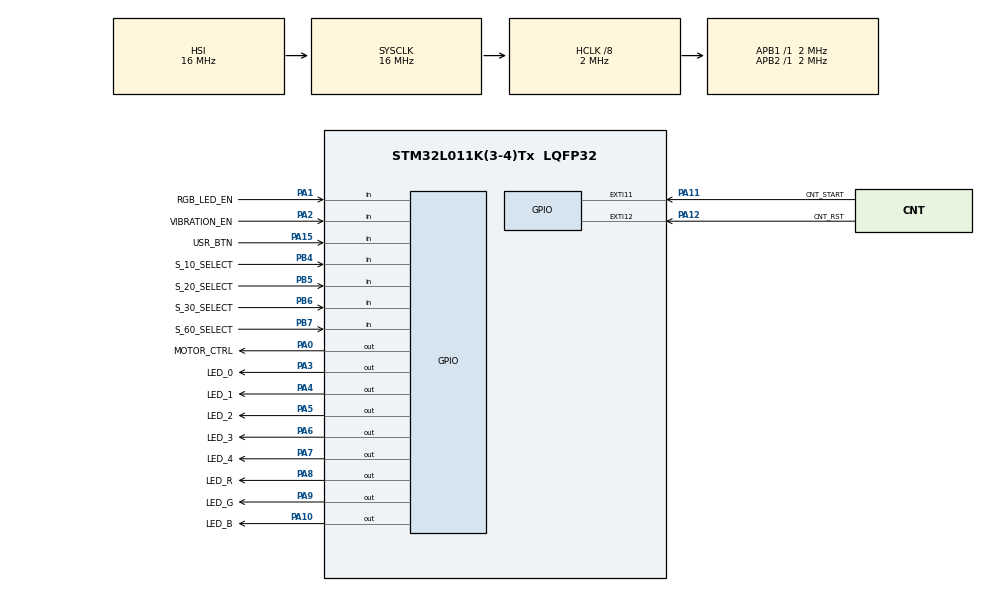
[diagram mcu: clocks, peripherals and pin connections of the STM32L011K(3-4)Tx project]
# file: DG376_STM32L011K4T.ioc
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Mcu.Family=STM32L0
Mcu.Name=STM32L011K(3-4)Tx
Mcu.Package=LQFP32
PA0-CK_IN.GPIO_Label=MOTOR_CTRL
PA0-CK_IN.Signal=GPIO_Output
PA1.GPIO_Label=RGB_LED_EN
PA1.GPIO_PuPd=GPIO_PULLDOWN
PA1.Signal=GPIO_Input
PA10.GPIO_Label=LED_B
PA10.Signal=GPIO_Output
PA11.GPIO_Label=CNT_START
PA11.GPIO_ModeDefaultEXTI=GPIO_MODE_IT_FALLING
PA11.GPIO_PuPd=GPIO_PULLUP
PA11.Signal=GPXTI11
PA12.GPIO_Label=CNT_RST
PA12.GPIO_PuPd=GPIO_PULLDOWN
PA12.Signal=GPXTI12
PA13.Mode=Serial_Wire
PA13.Signal=SYS_SWDIO
PA14.Mode=Serial_Wire
PA14.Signal=SYS_SWCLK
PA15.GPIO_Label=USR_BTN
PA15.GPIO_PuPd=GPIO_PULLUP
PA15.Signal=GPIO_Input
PA2.GPIO_Label=VIBRATION_EN
PA2.GPIO_PuPd=GPIO_PULLDOWN
PA2.Signal=GPIO_Input
PA3.GPIO_Label=LED_0
PA3.Signal=GPIO_Output
PA4.GPIO_Label=LED_1
PA4.Signal=GPIO_Output
PA5.GPIO_Label=LED_2
PA5.Signal=GPIO_Output
PA6.GPIO_Label=LED_3
PA6.Signal=GPIO_Output
PA7.GPIO_Label=LED_4
PA7.Signal=GPIO_Output
PA8.GPIO_Label=LED_R
PA8.Signal=GPIO_Output
PA9.GPIO_Label=LED_G
PA9.Signal=GPIO_Output
PB4.GPIO_Label=S_10_SELECT
PB4.GPIO_PuPd=GPIO_PULLDOWN
PB4.Signal=GPIO_Input
PB5.GPIO_Label=S_20_SELECT
PB5.GPIO_PuPd=GPIO_PULLDOWN
PB5.Signal=GPIO_Input
PB6.GPIO_Label=S_30_SELECT
PB6.GPIO_PuPd=GPIO_PULLDOWN
PB6.Signal=GPIO_Input
PB7.GPIO_Label=S_60_SELECT
PB7.GPIO_PuPd=GPIO_PULLDOWN
PB7.Signal=GPIO_Input
ProjectManager.HeapSize=0x200
ProjectManager.StackSize=0x400
ProjectManager.TargetToolchain=SW4STM32
RCC.ADCFreq_Value=16000000
RCC.AHBCLKDivider=RCC_SYSCLK_DIV8
RCC.AHBFreq_Value=2000000
RCC.APB1Freq_Value=2000000
RCC.APB1TimFreq_Value=2000000
RCC.APB2Freq_Value=2000000
RCC.APB2TimFreq_Value=2000000
RCC.HCLKFreq_Value=2000000
RCC.HSE_VALUE=8000000
RCC.HSI16_VALUE=16000000
RCC.HSI_VALUE=16000000
RCC.MSIClockRange=RCC_MSIRANGE_6
RCC.MSI_VALUE=4194000
RCC.SYSCLKFreq_VALUE=16000000
RCC.SYSCLKSource=RCC_SYSCLKSOURCE_HSI
RCC.VCOOutputFreq_Value=48000000
RCC.VDD_VALUE=3
VP_RTC_VS_RTC_Activate.Mode=RTC_Enabled
board=custom

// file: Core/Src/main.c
/* USER CODE BEGIN Header */
/**
 ******************************************************************************
 * @file           : main.c
 * @brief          : Main program body
 ******************************************************************************
 * @attention
 *
 * <h2><center>&copy; Copyright (c) 2020 STMicroelectronics.
 * All rights reserved.</center></h2>
 *
 * This software component is licensed by ST under BSD 3-Clause license,
 * the "License"; You may not use this file except in compliance with the
 * License. You may obtain a copy of the License at:
 *                        opensource.org/licenses/BSD-3-Clause
 *
 ******************************************************************************
 */
/* USER CODE END Header */

#include "main.h"

/* USER CODE BEGIN Includes */
#include "dg376_main.h"
/* USER CODE END Includes */

RTC_HandleTypeDef hrtc;

void SystemClock_Config(void);
static void MX_GPIO_Init(void);
static void MX_RTC_Init(void);

int main(void) {

  /* MCU Configuration--------------------------------------------------------*/

  /* Reset of all peripherals, Initializes the Flash interface and the Systick.
   */
  HAL_Init();

  /* Configure the system clock */
  SystemClock_Config();

  /* Initialize all configured peripherals */
  MX_GPIO_Init();
  MX_RTC_Init();

  /* Infinite loop */
  /* USER CODE BEGIN WHILE */
  while (1) {
    dg376_while_loop();
    /* USER CODE END WHILE */
  }
}

void SystemClock_Config(void) {
  RCC_OscInitTypeDef RCC_OscInitStruct = {0};
  RCC_ClkInitTypeDef RCC_ClkInitStruct = {0};
  RCC_PeriphCLKInitTypeDef PeriphClkInit = {0};

  /** Configure the main internal regulator output voltage
   */
  __HAL_PWR_VOLTAGESCALING_CONFIG(PWR_REGULATOR_VOLTAGE_SCALE1);
  /** Initializes the CPU, AHB and APB busses clocks
   */
  RCC_OscInitStruct.OscillatorType =
      RCC_OSCILLATORTYPE_HSI | RCC_OSCILLATORTYPE_LSI;
  RCC_OscInitStruct.HSIState = RCC_HSI_ON;
  RCC_OscInitStruct.HSICalibrationValue = RCC_HSICALIBRATION_DEFAULT;
  RCC_OscInitStruct.LSIState = RCC_LSI_ON;
  RCC_OscInitStruct.PLL.PLLState = RCC_PLL_NONE;
  if (HAL_RCC_OscConfig(&RCC_OscInitStruct) != HAL_OK) {
    Error_Handler();
  }
  /** Initializes the CPU, AHB and APB busses clocks
   */
  RCC_ClkInitStruct.ClockType = RCC_CLOCKTYPE_HCLK | RCC_CLOCKTYPE_SYSCLK |
                                RCC_CLOCKTYPE_PCLK1 | RCC_CLOCKTYPE_PCLK2;
  RCC_ClkInitStruct.SYSCLKSource = RCC_SYSCLKSOURCE_HSI;
  RCC_ClkInitStruct.AHBCLKDivider = RCC_SYSCLK_DIV8;
  RCC_ClkInitStruct.APB1CLKDivider = RCC_HCLK_DIV1;
  RCC_ClkInitStruct.APB2CLKDivider = RCC_HCLK_DIV1;

  if (HAL_RCC_ClockConfig(&RCC_ClkInitStruct, FLASH_LATENCY_0) != HAL_OK) {
    Error_Handler();
  }
  PeriphClkInit.PeriphClockSelection = RCC_PERIPHCLK_RTC;
  PeriphClkInit.RTCClockSelection = RCC_RTCCLKSOURCE_LSI;
  if (HAL_RCCEx_PeriphCLKConfig(&PeriphClkInit) != HAL_OK) {
    Error_Handler();
  }
}

static void MX_RTC_Init(void) {

  /** Initialize RTC Only
   */
  hrtc.Instance = RTC;
  hrtc.Init.HourFormat = RTC_HOURFORMAT_24;
  hrtc.Init.AsynchPrediv = 127;
  hrtc.Init.SynchPrediv = 255;
  hrtc.Init.OutPut = RTC_OUTPUT_DISABLE;
  hrtc.Init.OutPutRemap = RTC_OUTPUT_REMAP_NONE;
  hrtc.Init.OutPutPolarity = RTC_OUTPUT_POLARITY_HIGH;
  hrtc.Init.OutPutType = RTC_OUTPUT_TYPE_OPENDRAIN;
  if (HAL_RTC_Init(&hrtc) != HAL_OK) {
    Error_Handler();
  }
}

static void MX_GPIO_Init(void) {
  GPIO_InitTypeDef GPIO_InitStruct = {0};

  /* GPIO Ports Clock Enable */
  __HAL_RCC_GPIOA_CLK_ENABLE();
  __HAL_RCC_GPIOB_CLK_ENABLE();

  /*Configure GPIO pin Output Level */
  HAL_GPIO_WritePin(GPIOA,
                    MOTOR_CTRL_Pin | LED_0_Pin | LED_1_Pin | LED_2_Pin |
                        LED_3_Pin | LED_4_Pin | LED_R_Pin | LED_G_Pin |
                        LED_B_Pin,
                    GPIO_PIN_RESET);

  /*Configure GPIO pins : MOTOR_CTRL_Pin LED_0_Pin LED_1_Pin LED_2_Pin
                           LED_3_Pin LED_4_Pin LED_R_Pin LED_G_Pin
                           LED_B_Pin */
  GPIO_InitStruct.Pin = MOTOR_CTRL_Pin | LED_0_Pin | LED_1_Pin | LED_2_Pin |
                        LED_3_Pin | LED_4_Pin | LED_R_Pin | LED_G_Pin |
                        LED_B_Pin;
  GPIO_InitStruct.Mode = GPIO_MODE_OUTPUT_PP;
  GPIO_InitStruct.Pull = GPIO_NOPULL;
  GPIO_InitStruct.Speed = GPIO_SPEED_FREQ_LOW;
  HAL_GPIO_Init(GPIOA, &GPIO_InitStruct);

  /*Configure GPIO pins : RGB_LED_EN_Pin VIBRATION_EN_Pin */
  GPIO_InitStruct.Pin = RGB_LED_EN_Pin | VIBRATION_EN_Pin;
  GPIO_InitStruct.Mode = GPIO_MODE_INPUT;
  GPIO_InitStruct.Pull = GPIO_PULLDOWN;
  HAL_GPIO_Init(GPIOA, &GPIO_InitStruct);

  /*Configure GPIO pin : CNT_START_Pin */
  GPIO_InitStruct.Pin = CNT_START_Pin;
  GPIO_InitStruct.Mode = GPIO_MODE_IT_FALLING;
  GPIO_InitStruct.Pull = GPIO_PULLUP;
  HAL_GPIO_Init(CNT_START_GPIO_Port, &GPIO_InitStruct);

  /*Configure GPIO pin : CNT_RST_Pin */
  GPIO_InitStruct.Pin = CNT_RST_Pin;
  GPIO_InitStruct.Mode = GPIO_MODE_IT_RISING;
  GPIO_InitStruct.Pull = GPIO_PULLDOWN;
  HAL_GPIO_Init(CNT_RST_GPIO_Port, &GPIO_InitStruct);

  /*Configure GPIO pin : USR_BTN_Pin */
  GPIO_InitStruct.Pin = USR_BTN_Pin;
  GPIO_InitStruct.Mode = GPIO_MODE_INPUT;
  GPIO_InitStruct.Pull = GPIO_PULLUP;
  HAL_GPIO_Init(USR_BTN_GPIO_Port, &GPIO_InitStruct);

  /*Configure GPIO pins : S_10_SELECT_Pin S_20_SELECT_Pin S_30_SELECT_Pin
   * S_60_SELECT_Pin */
  GPIO_InitStruct.Pin =
      S_10_SELECT_Pin | S_20_SELECT_Pin | S_30_SELECT_Pin | S_60_SELECT_Pin;
  GPIO_InitStruct.Mode = GPIO_MODE_INPUT;
  GPIO_InitStruct.Pull = GPIO_PULLDOWN;
  HAL_GPIO_Init(GPIOB, &GPIO_InitStruct);
}

void Error_Handler(void) {
}

#ifdef USE_FULL_ASSERT
/**
 * @brief  Reports the name of the source file and the source line number
 *         where the assert_param error has occurred.
 * @param  file: pointer to the source file name
 * @param  line: assert_param error line source number
 * @retval None
 */
void assert_failed(uint8_t *file, uint32_t line) {
  /* USER CODE BEGIN 6 */
  /* User can add his own implementation to report the file name and line
     number,
     tex: printf("Wrong parameters value: file %s on line %d\r\n", file, line)
   */
  /* USER CODE END 6 */
}
#endif /* USE_FULL_ASSERT */

/************************ (C) COPYRIGHT STMicroelectronics *****END OF FILE****/
